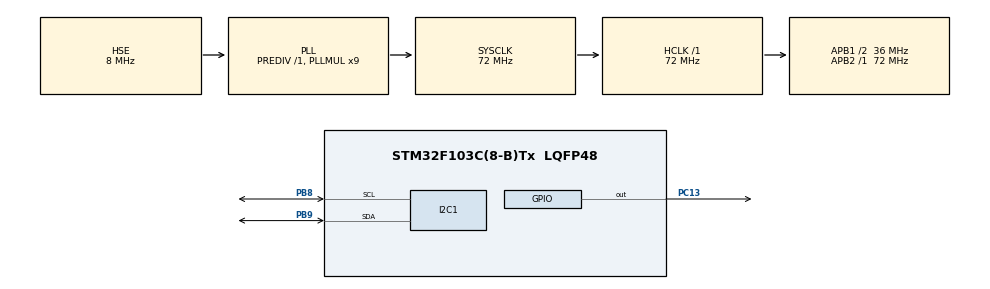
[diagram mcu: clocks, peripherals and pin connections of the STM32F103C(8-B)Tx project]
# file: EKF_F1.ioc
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Mcu.Family=STM32F1
Mcu.Name=STM32F103C(8-B)Tx
Mcu.Package=LQFP48
NVIC.PriorityGroup=NVIC_PRIORITYGROUP_4
PA13.Mode=Serial_Wire
PA13.Signal=SYS_JTMS-SWDIO
PA14.Mode=Serial_Wire
PA14.Signal=SYS_JTCK-SWCLK
PB8.Mode=I2C
PB8.Signal=I2C1_SCL
PB9.Mode=I2C
PB9.Signal=I2C1_SDA
PC13-TAMPER-RTC.Signal=GPIO_Output
PD0-OSC_IN.Mode=HSE-External-Oscillator
PD0-OSC_IN.Signal=RCC_OSC_IN
PD1-OSC_OUT.Mode=HSE-External-Oscillator
PD1-OSC_OUT.Signal=RCC_OSC_OUT
ProjectManager.HeapSize=0x200
ProjectManager.StackSize=0x400
ProjectManager.TargetToolchain=STM32CubeIDE
RCC.AHBFreq_Value=72000000
RCC.APB1CLKDivider=RCC_HCLK_DIV2
RCC.APB1Freq_Value=36000000
RCC.APB1TimFreq_Value=72000000
RCC.APB2Freq_Value=72000000
RCC.APB2TimFreq_Value=72000000
RCC.HCLKFreq_Value=72000000
RCC.PLLMUL=RCC_PLL_MUL9
RCC.PLLSourceVirtual=RCC_PLLSOURCE_HSE
RCC.SYSCLKFreq_VALUE=72000000
RCC.SYSCLKSource=RCC_SYSCLKSOURCE_PLLCLK
RCC.USBFreq_Value=72000000
TIM4.Prescaler=71
VP_TIM4_VS_ClockSourceINT.Mode=Internal
board=custom

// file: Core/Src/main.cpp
/* USER CODE BEGIN Header */
/**
  ******************************************************************************
  * @file           : main.c
  * @brief          : Main program body
  ******************************************************************************
  * @attention
  *
  * <h2><center>&copy; Copyright (c) 2021 STMicroelectronics.
  * All rights reserved.</center></h2>
  *
  * This software component is licensed by ST under BSD 3-Clause license,
  * the "License"; You may not use this file except in compliance with the
  * License. You may obtain a copy of the License at:
  *                        opensource.org/licenses/BSD-3-Clause
  *
  ******************************************************************************
  */
/* USER CODE END Header */
#include "main.h"

/* USER CODE BEGIN Includes */
#define ARM_MATH_CM3

#include "arm_math.h"
#include "mpu9250.hpp"
#include "EKF2.h"
#include "calib_magnet.h"
/* USER CODE END Includes */

I2C_HandleTypeDef hi2c1;
TIM_HandleTypeDef htim4;

void SystemClock_Config(void);
static void MX_GPIO_Init(void);
static void MX_I2C1_Init(void);
static void MX_TIM4_Init(void);

/* USER CODE BEGIN 0 */
IMU_data data_imu_temp;
IMU_data data_imu_raw;
IMU_data data_imu_buffer;
IMU_data data_imu_com;
MAG_data mag;
float dt = 0.01;
EKF2 ekf;

/* USER CODE END 0 */

int main(void)
{

  /* MCU Configuration--------------------------------------------------------*/

  /* Reset of all peripherals, Initializes the Flash interface and the Systick. */
  HAL_Init();

  /* Configure the system clock */
  SystemClock_Config();

  /* Initialize all configured peripherals */
  MX_GPIO_Init();
  MX_I2C1_Init();
  MX_TIM4_Init();
  /* USER CODE BEGIN 2 */
  ekf.x_[4] = bGx * DEC2RAD;
   ekf.x_[5] = bGy * DEC2RAD;
   ekf.x_[6] = bGz * DEC2RAD;

 //  ekf.x4 = bGx * DEC2RAD;
 //   ekf.x4 = bGy * DEC2RAD;
 //   ekf.x6 = bGz * DEC2RAD;

   ekf.loadEKF();
   HAL_TIM_Base_Start(&htim4);
  /* USER CODE END 2 */

  /* Infinite loop */
  while (1)
  {

    /* USER CODE BEGIN 3 */
	  int start = TIM4->CNT;
//	  data_imu_buffer = process_MPU(true, true);
	  ekf.updateEKF(data_imu_buffer,mag, 0.01);
//	  mag = magnet_get_raw();

//      HAL_Delay(10);
	  int stop = TIM4->CNT;
	  HAL_GPIO_TogglePin(GPIOC,GPIO_PIN_13);
	  int time = stop - start;
  }
  /* USER CODE END 3 */
}

void SystemClock_Config(void)
{
  RCC_OscInitTypeDef RCC_OscInitStruct = {0};
  RCC_ClkInitTypeDef RCC_ClkInitStruct = {0};

  /** Initializes the RCC Oscillators according to the specified parameters
  * in the RCC_OscInitTypeDef structure.
  */
  RCC_OscInitStruct.OscillatorType = RCC_OSCILLATORTYPE_HSE;
  RCC_OscInitStruct.HSEState = RCC_HSE_ON;
  RCC_OscInitStruct.HSEPredivValue = RCC_HSE_PREDIV_DIV1;
  RCC_OscInitStruct.HSIState = RCC_HSI_ON;
  RCC_OscInitStruct.PLL.PLLState = RCC_PLL_ON;
  RCC_OscInitStruct.PLL.PLLSource = RCC_PLLSOURCE_HSE;
  RCC_OscInitStruct.PLL.PLLMUL = RCC_PLL_MUL9;
  if (HAL_RCC_OscConfig(&RCC_OscInitStruct) != HAL_OK)
  {
    Error_Handler();
  }
  /** Initializes the CPU, AHB and APB buses clocks
  */
  RCC_ClkInitStruct.ClockType = RCC_CLOCKTYPE_HCLK|RCC_CLOCKTYPE_SYSCLK
                              |RCC_CLOCKTYPE_PCLK1|RCC_CLOCKTYPE_PCLK2;
  RCC_ClkInitStruct.SYSCLKSource = RCC_SYSCLKSOURCE_PLLCLK;
  RCC_ClkInitStruct.AHBCLKDivider = RCC_SYSCLK_DIV1;
  RCC_ClkInitStruct.APB1CLKDivider = RCC_HCLK_DIV2;
  RCC_ClkInitStruct.APB2CLKDivider = RCC_HCLK_DIV1;

  if (HAL_RCC_ClockConfig(&RCC_ClkInitStruct, FLASH_LATENCY_2) != HAL_OK)
  {
    Error_Handler();
  }
}

static void MX_I2C1_Init(void)
{

  hi2c1.Instance = I2C1;
  hi2c1.Init.ClockSpeed = 100000;
  hi2c1.Init.DutyCycle = I2C_DUTYCYCLE_2;
  hi2c1.Init.OwnAddress1 = 0;
  hi2c1.Init.AddressingMode = I2C_ADDRESSINGMODE_7BIT;
  hi2c1.Init.DualAddressMode = I2C_DUALADDRESS_DISABLE;
  hi2c1.Init.OwnAddress2 = 0;
  hi2c1.Init.GeneralCallMode = I2C_GENERALCALL_DISABLE;
  hi2c1.Init.NoStretchMode = I2C_NOSTRETCH_DISABLE;
  if (HAL_I2C_Init(&hi2c1) != HAL_OK)
  {
    Error_Handler();
  }

}

static void MX_TIM4_Init(void)
{

  TIM_ClockConfigTypeDef sClockSourceConfig = {0};
  TIM_MasterConfigTypeDef sMasterConfig = {0};

  htim4.Instance = TIM4;
  htim4.Init.Prescaler = 71;
  htim4.Init.CounterMode = TIM_COUNTERMODE_UP;
  htim4.Init.Period = 65535;
  htim4.Init.ClockDivision = TIM_CLOCKDIVISION_DIV1;
  htim4.Init.AutoReloadPreload = TIM_AUTORELOAD_PRELOAD_DISABLE;
  if (HAL_TIM_Base_Init(&htim4) != HAL_OK)
  {
    Error_Handler();
  }
  sClockSourceConfig.ClockSource = TIM_CLOCKSOURCE_INTERNAL;
  if (HAL_TIM_ConfigClockSource(&htim4, &sClockSourceConfig) != HAL_OK)
  {
    Error_Handler();
  }
  sMasterConfig.MasterOutputTrigger = TIM_TRGO_RESET;
  sMasterConfig.MasterSlaveMode = TIM_MASTERSLAVEMODE_DISABLE;
  if (HAL_TIMEx_MasterConfigSynchronization(&htim4, &sMasterConfig) != HAL_OK)
  {
    Error_Handler();
  }

}

static void MX_GPIO_Init(void)
{
  GPIO_InitTypeDef GPIO_InitStruct = {0};

  /* GPIO Ports Clock Enable */
  __HAL_RCC_GPIOC_CLK_ENABLE();
  __HAL_RCC_GPIOA_CLK_ENABLE();
  __HAL_RCC_GPIOB_CLK_ENABLE();

  /*Configure GPIO pin Output Level */
  HAL_GPIO_WritePin(GPIOC, GPIO_PIN_13, GPIO_PIN_RESET);

  /*Configure GPIO pin : PC13 */
  GPIO_InitStruct.Pin = GPIO_PIN_13;
  GPIO_InitStruct.Mode = GPIO_MODE_OUTPUT_PP;
  GPIO_InitStruct.Pull = GPIO_NOPULL;
  GPIO_InitStruct.Speed = GPIO_SPEED_FREQ_LOW;
  HAL_GPIO_Init(GPIOC, &GPIO_InitStruct);

}

void Error_Handler(void)
{
  __disable_irq();
  while (1)
  {
  }
}

/************************ (C) COPYRIGHT STMicroelectronics *****END OF FILE****/
